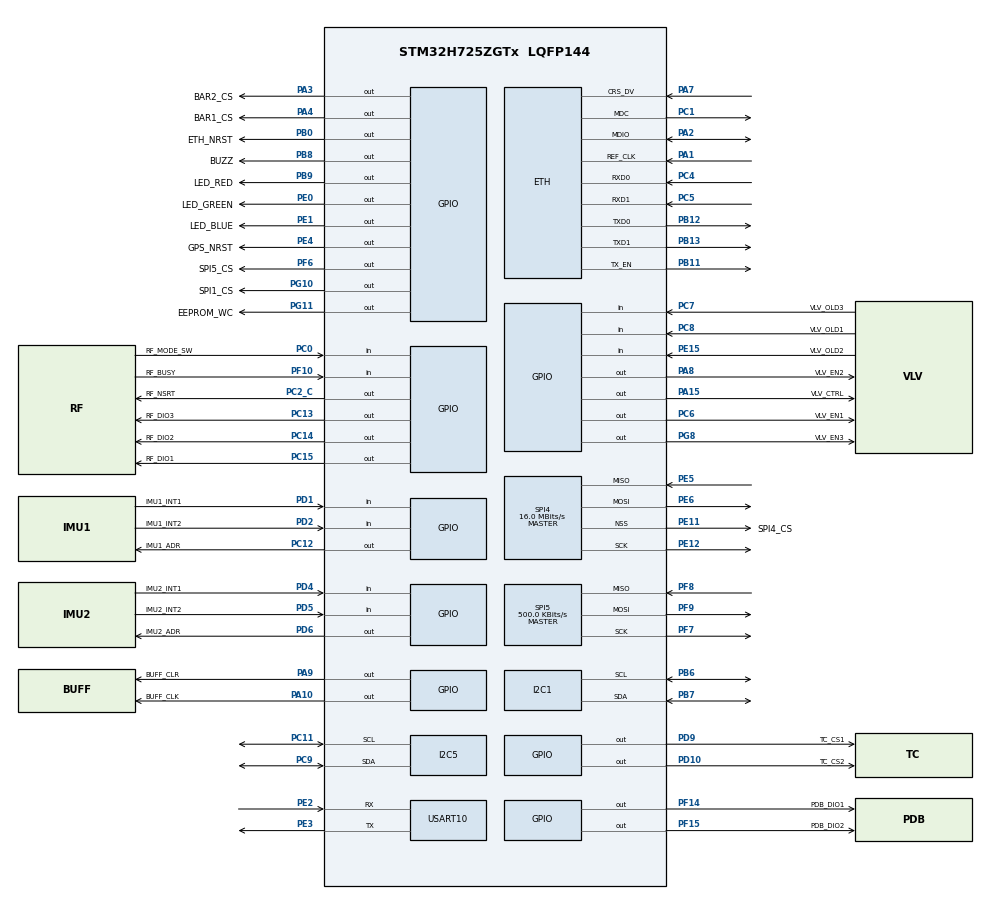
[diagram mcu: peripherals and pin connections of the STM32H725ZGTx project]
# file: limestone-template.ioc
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CORTEX_M7.AccessPermission-Cortex_Memory_Protection_Unit_Region0_Settings=MPU_REGION_NO_ACCESS
CORTEX_M7.AccessPermission-Cortex_Memory_Protection_Unit_Region1_Settings=MPU_REGION_FULL_ACCESS
CORTEX_M7.AccessPermission-Cortex_Memory_Protection_Unit_Region2_Settings=MPU_REGION_FULL_ACCESS
CORTEX_M7.AccessPermission_S-Cortex_Memory_Protection_Unit_Region1_Settings_S=MPU_REGION_FULL_ACCESS
CORTEX_M7.AccessPermission_S-Cortex_Memory_Protection_Unit_Region2_Settings_S=MPU_REGION_FULL_ACCESS
CORTEX_M7.AccessPermission_Spec=MPU_REGION_NO_ACCESS
CORTEX_M7.BaseAddress-Cortex_Memory_Protection_Unit_Region0_Settings=0x00000000
CORTEX_M7.BaseAddress-Cortex_Memory_Protection_Unit_Region1_Settings=0x30000200
CORTEX_M7.BaseAddress-Cortex_Memory_Protection_Unit_Region2_Settings=0x30000000
CORTEX_M7.BaseAddress_S-Cortex_Memory_Protection_Unit_Region1_Settings_S=0x30020000
CORTEX_M7.BaseAddress_S-Cortex_Memory_Protection_Unit_Region2_Settings_S=0x30040000
CORTEX_M7.CPU_DCache=Enabled
CORTEX_M7.CPU_ICache=Enabled
CORTEX_M7.DisableExec-Cortex_Memory_Protection_Unit_Region0_Settings=MPU_INSTRUCTION_ACCESS_DISABLE
CORTEX_M7.DisableExec-Cortex_Memory_Protection_Unit_Region1_Settings=MPU_INSTRUCTION_ACCESS_DISABLE
CORTEX_M7.DisableExec-Cortex_Memory_Protection_Unit_Region2_Settings=MPU_INSTRUCTION_ACCESS_DISABLE
CORTEX_M7.DisableExec_S-Cortex_Memory_Protection_Unit_Region1_Settings_S=MPU_INSTRUCTION_ACCESS_DISABLE
CORTEX_M7.DisableExec_S-Cortex_Memory_Protection_Unit_Region2_Settings_S=MPU_INSTRUCTION_ACCESS_DISABLE
CORTEX_M7.Enable-Cortex_Memory_Protection_Unit_Region0_Settings=MPU_REGION_ENABLE
CORTEX_M7.Enable-Cortex_Memory_Protection_Unit_Region1_Settings=MPU_REGION_ENABLE
CORTEX_M7.Enable-Cortex_Memory_Protection_Unit_Region2_Settings=MPU_REGION_ENABLE
CORTEX_M7.Enable_S-Cortex_Memory_Protection_Unit_Region1_Settings_S=MPU_REGION_ENABLE
CORTEX_M7.Enable_S-Cortex_Memory_Protection_Unit_Region2_Settings_S=MPU_REGION_ENABLE
CORTEX_M7.IsBufferable-Cortex_Memory_Protection_Unit_Region1_Settings=MPU_ACCESS_NOT_BUFFERABLE
CORTEX_M7.IsBufferable-Cortex_Memory_Protection_Unit_Region2_Settings=MPU_ACCESS_BUFFERABLE
CORTEX_M7.IsBufferable_S-Cortex_Memory_Protection_Unit_Region2_Settings_S=MPU_ACCESS_BUFFERABLE
CORTEX_M7.IsCacheable-Cortex_Memory_Protection_Unit_Region1_Settings=MPU_ACCESS_NOT_CACHEABLE
CORTEX_M7.IsShareable-Cortex_Memory_Protection_Unit_Region0_Settings=MPU_ACCESS_SHAREABLE
CORTEX_M7.IsShareable-Cortex_Memory_Protection_Unit_Region2_Settings=MPU_ACCESS_SHAREABLE
CORTEX_M7.IsShareable_S-Cortex_Memory_Protection_Unit_Region1_Settings_S=MPU_ACCESS_NOT_SHAREABLE
CORTEX_M7.IsShareable_S-Cortex_Memory_Protection_Unit_Region2_Settings_S=MPU_ACCESS_SHAREABLE
CORTEX_M7.MPU_Control=MPU_PRIVILEGED_DEFAULT
CORTEX_M7.Size-Cortex_Memory_Protection_Unit_Region0_Settings=MPU_REGION_SIZE_4GB
CORTEX_M7.Size-Cortex_Memory_Protection_Unit_Region1_Settings=MPU_REGION_SIZE_128KB
CORTEX_M7.Size-Cortex_Memory_Protection_Unit_Region2_Settings=MPU_REGION_SIZE_512B
CORTEX_M7.Size_S-Cortex_Memory_Protection_Unit_Region1_Settings_S=MPU_REGION_SIZE_128KB
CORTEX_M7.Size_S-Cortex_Memory_Protection_Unit_Region2_Settings_S=MPU_REGION_SIZE_512B
CORTEX_M7.SubRegionDisable-Cortex_Memory_Protection_Unit_Region0_Settings=0x87
CORTEX_M7.SubRegionDisable_S-Cortex_Memory_Protection_Unit_Region1_Settings_S=0x0
CORTEX_M7.TypeExtField-Cortex_Memory_Protection_Unit_Region1_Settings=MPU_TEX_LEVEL1
CORTEX_M7.TypeExtField_S-Cortex_Memory_Protection_Unit_Region1_Settings_S=MPU_TEX_LEVEL1
CORTEX_M7.default_mode_Activation=1
ETH.MediaInterface=HAL_ETH_RMII_MODE
ETH.RxBuffLen=1524
ETH.TxDescAddress=0x30000080
FREERTOS.Tasks01=defaultTask,24,512,StartDefaultTask,Default,NULL,Dynamic,NULL,NULL
FREERTOS.configUSE_NEWLIB_REENTRANT=1
I2C1.Timing=0x00707CBB
I2C5.Timing=0x00707CBB
Mcu.Family=STM32H7
Mcu.Name=STM32H725ZGTx
Mcu.Package=LQFP144
NVIC.ETH_IRQn=true\:5\:0\:true\:false\:true\:true\:true\:true\:true
NVIC.PriorityGroup=NVIC_PRIORITYGROUP_4
NVIC.TIM6_DAC_IRQn=true\:15\:0\:false\:false\:true\:false\:false\:true\:true
NVIC.TimeBase=TIM6_DAC_IRQn
NVIC.TimeBaseIP=TIM6
PA1.GPIO_Speed=GPIO_SPEED_FREQ_VERY_HIGH
PA1.Mode=RMII
PA1.Signal=ETH_REF_CLK
PA10.GPIO_Label=BUFF_CLK
PA10.GPIO_Speed=GPIO_SPEED_FREQ_VERY_HIGH
PA10.Signal=GPIO_Output
PA13(JTMS/SWDIO).Mode=Serial_Wire
PA13(JTMS/SWDIO).Signal=DEBUG_JTMS-SWDIO
PA14(JTCK/SWCLK).Mode=Serial_Wire
PA14(JTCK/SWCLK).Signal=DEBUG_JTCK-SWCLK
PA15(JTDI).GPIO_Label=VLV_CTRL
PA15(JTDI).GPIO_PuPd=GPIO_NOPULL
PA15(JTDI).GPIO_Speed=GPIO_SPEED_FREQ_VERY_HIGH
PA15(JTDI).Signal=GPIO_Output
PA2.GPIO_Speed=GPIO_SPEED_FREQ_VERY_HIGH
PA2.Mode=RMII
PA2.Signal=ETH_MDIO
PA3.GPIO_Label=BAR2_CS
PA3.Signal=GPIO_Output
PA4.GPIO_Label=BAR1_CS
PA4.Signal=GPIO_Output
PA6.Signal=SPI1_MISO
PA7.GPIO_Speed=GPIO_SPEED_FREQ_VERY_HIGH
PA7.Mode=RMII
PA7.Signal=ETH_CRS_DV
PA8.GPIO_Label=VLV_EN2
PA8.Signal=GPIO_Output
PA9.GPIO_Label=BUFF_CLR
PA9.GPIO_Speed=GPIO_SPEED_FREQ_VERY_HIGH
PA9.Signal=GPIO_Output
PB0.GPIO_Label=ETH_NRST
PB0.Signal=GPIO_Output
PB10.Signal=SPI2_SCK
PB11.GPIO_Speed=GPIO_SPEED_FREQ_VERY_HIGH
PB11.Mode=RMII
PB11.Signal=ETH_TX_EN
PB12.GPIO_Speed=GPIO_SPEED_FREQ_VERY_HIGH
PB12.Mode=RMII
PB12.Signal=ETH_TXD0
PB13.GPIO_Speed=GPIO_SPEED_FREQ_VERY_HIGH
PB13.Mode=RMII
PB13.Signal=ETH_TXD1
PB14.Signal=SPI2_MISO
PB15.Signal=SPI2_MOSI
PB2.Signal=SPI3_MOSI
PB3(JTDO/TRACESWO).Signal=SPI1_SCK
PB4(NJTRST).Signal=SPI3_MISO
PB5.Signal=SPI1_MOSI
PB6.Mode=I2C
PB6.Signal=I2C1_SCL
PB7.Mode=I2C
PB7.Signal=I2C1_SDA
PB8.GPIO_Label=BUZZ
PB8.Signal=GPIO_Output
PB9.GPIO_Label=LED_RED
PB9.Signal=GPIO_Output
PC0.GPIO_Label=RF_MODE_SW
PC0.Signal=GPIO_Input
PC1.GPIO_Speed=GPIO_SPEED_FREQ_VERY_HIGH
PC1.Mode=RMII
PC1.Signal=ETH_MDC
PC10.Signal=SPI3_SCK
PC11.Mode=I2C
PC11.Signal=I2C5_SCL
PC12.GPIO_Label=IMU1_ADR
PC12.Signal=GPIO_Output
PC13.GPIO_Label=RF_DIO3
PC13.Signal=GPIO_Output
PC14-OSC32_IN.GPIO_Label=RF_DIO2
PC14-OSC32_IN.Signal=GPIO_Output
PC15-OSC32_OUT.GPIO_Label=RF_DIO1
PC15-OSC32_OUT.Signal=GPIO_Output
PC2_C.GPIO_Label=RF_NSRT
PC2_C.Signal=GPIO_Output
PC4.GPIO_Speed=GPIO_SPEED_FREQ_VERY_HIGH
PC4.Mode=RMII
PC4.Signal=ETH_RXD0
PC5.GPIO_Speed=GPIO_SPEED_FREQ_VERY_HIGH
PC5.Mode=RMII
PC5.Signal=ETH_RXD1
PC6.GPIO_Label=VLV_EN1
PC6.Signal=GPIO_Output
PC7.GPIO_Label=VLV_OLD3
PC7.Signal=GPIO_Input
PC8.GPIO_Label=VLV_OLD1
PC8.Signal=GPIO_Input
PC9.Mode=I2C
PC9.Signal=I2C5_SDA
PD1.GPIO_Label=IMU1_INT1
PD1.Signal=GPIO_Input
PD10.GPIO_Label=TC_CS2
PD10.Signal=GPIO_Output
PD2.GPIO_Label=IMU1_INT2
PD2.Signal=GPIO_Input
PD4.GPIO_Label=IMU2_INT1
PD4.Signal=GPIO_Input
PD5.GPIO_Label=IMU2_INT2
PD5.Signal=GPIO_Input
PD6.GPIO_Label=IMU2_ADR
PD6.Signal=GPIO_Output
PD9.GPIO_Label=TC_CS1
PD9.Signal=GPIO_Output
PE0.GPIO_Label=LED_GREEN
PE0.Signal=GPIO_Output
PE1.GPIO_Label=LED_BLUE
PE1.Signal=GPIO_Output
PE11.GPIO_Label=SPI4_CS
PE11.Mode=NSS_Signal_Hard_Output
PE11.Signal=SPI4_NSS
PE12.Mode=Full_Duplex_Master
PE12.Signal=SPI4_SCK
PE15.GPIO_Label=VLV_OLD2
PE15.Signal=GPIO_Input
PE2.Mode=Asynchronous
PE2.Signal=USART10_RX
PE3.Mode=Asynchronous
PE3.Signal=USART10_TX
PE4.GPIO_Label=GPS_NRST
PE4.Signal=GPIO_Output
PE5.Mode=Full_Duplex_Master
PE5.Signal=SPI4_MISO
PE6.Mode=Full_Duplex_Master
PE6.Signal=SPI4_MOSI
PF10.GPIO_Label=RF_BUSY
PF10.Signal=GPIO_Input
PF14.GPIO_Label=PDB_DIO1
PF14.Signal=GPIO_Output
PF15.GPIO_Label=PDB_DIO2
PF15.Signal=GPIO_Output
PF6.GPIO_Label=SPI5_CS
PF6.Signal=GPIO_Output
PF7.Mode=Full_Duplex_Master
PF7.Signal=SPI5_SCK
PF8.Mode=Full_Duplex_Master
PF8.Signal=SPI5_MISO
PF9.Mode=Full_Duplex_Master
PF9.Signal=SPI5_MOSI
PG10.GPIO_Label=SPI1_CS
PG10.Signal=GPIO_Output
PG11.GPIO_Label=EEPROM_WC
PG11.Signal=GPIO_Output
PG12.Signal=SPI6_MISO
PG14.Signal=SPI6_MOSI
PG8.GPIO_Label=VLV_EN3
PG8.Signal=GPIO_Output
ProjectManager.HeapSize=0x200
ProjectManager.StackSize=0x400
ProjectManager.TargetToolchain=STM32CubeIDE
RCC.ADCFreq_Value=516000000
RCC.APB1Freq_Value=32000000
RCC.APB2Freq_Value=32000000
RCC.APB3Freq_Value=32000000
RCC.APB4Freq_Value=32000000
RCC.CortexFreq_Value=64000000
RCC.D1PPRE=RCC_APB3_DIV2
RCC.D2PPRE1=RCC_APB1_DIV2
RCC.D2PPRE2=RCC_APB2_DIV2
RCC.D3PPRE=RCC_APB4_DIV2
RCC.DIVM1=4
RCC.DIVM2=8
RCC.DIVM3=8
RCC.DIVN1=12
RCC.DIVP1=3
RCC.DIVQ1=3
RCC.HCLKFreq_Value=64000000
RCC.HSE_VALUE=48000000
RCC.PLL2FRACN=0
RCC.PLL3FRACN=0
RCC.PLLFRACN=0
RCC.SYSCLKFreq_VALUE=64000000
RCC.SYSCLKSource=RCC_SYSCLKSOURCE_PLLCLK
RCC.SupplySource=PWR_LDO_SUPPLY
RCC.USBFreq_Value=64000000
SPI4.CalculateBaudRate=16.0 MBits/s
SPI4.DataSize=SPI_DATASIZE_8BIT
SPI4.Direction=SPI_DIRECTION_2LINES
SPI4.Mode=SPI_MODE_MASTER
SPI4.VirtualNSS=VM_NSSHARD
SPI4.VirtualType=VM_MASTER
SPI5.BaudRatePrescaler=SPI_BAUDRATEPRESCALER_64
SPI5.CalculateBaudRate=500.0 KBits/s
SPI5.DataSize=SPI_DATASIZE_8BIT
SPI5.Direction=SPI_DIRECTION_2LINES
SPI5.Mode=SPI_MODE_MASTER
SPI5.VirtualType=VM_MASTER
USART10.VirtualMode-Asynchronous=VM_ASYNC
VP_FREERTOS_VS_CMSIS_V2.Mode=CMSIS_V2
VP_MEMORYMAP_VS_MEMORYMAP.Mode=CurAppReg
VP_RTC_VS_RTC_Activate.Mode=RTC_Enabled
VP_SYS_VS_tim6.Mode=TIM6
board=custom

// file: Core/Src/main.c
/* USER CODE BEGIN Header */
/**
  ******************************************************************************
  * @file           : main.c
  * @brief          : Main program body
  ******************************************************************************
  * @attention
  *
  * Copyright (c) 2024 STMicroelectronics.
  * All rights reserved.
  *
  * This software is licensed under terms that can be found in the LICENSE file
  * in the root directory of this software component.
  * If no LICENSE file comes with this software, it is provided AS-IS.
  *
  ******************************************************************************
  */
/* USER CODE END Header */
#include "main.h"
#include "string.h"
#include "cmsis_os.h"

/* USER CODE BEGIN Includes */
#include "MS5611.h"
/* USER CODE END Includes */

#if defined ( __ICCARM__ ) /*!< IAR Compiler */
#pragma location=0x30000000
ETH_DMADescTypeDef  DMARxDscrTab[ETH_RX_DESC_CNT]; /* Ethernet Rx DMA Descriptors */
#pragma location=0x30000080
ETH_DMADescTypeDef  DMATxDscrTab[ETH_TX_DESC_CNT]; /* Ethernet Tx DMA Descriptors */

#elif defined ( __CC_ARM )  /* MDK ARM Compiler */

__attribute__((at(0x30000000))) ETH_DMADescTypeDef  DMARxDscrTab[ETH_RX_DESC_CNT]; /* Ethernet Rx DMA Descriptors */
__attribute__((at(0x30000080))) ETH_DMADescTypeDef  DMATxDscrTab[ETH_TX_DESC_CNT]; /* Ethernet Tx DMA Descriptors */

#elif defined ( __GNUC__ ) /* GNU Compiler */

ETH_DMADescTypeDef DMARxDscrTab[ETH_RX_DESC_CNT] __attribute__((section(".RxDescripSection"))); /* Ethernet Rx DMA Descriptors */
ETH_DMADescTypeDef DMATxDscrTab[ETH_TX_DESC_CNT] __attribute__((section(".TxDescripSection")));   /* Ethernet Tx DMA Descriptors */
#endif

ETH_TxPacketConfig TxConfig;

ETH_HandleTypeDef heth;

I2C_HandleTypeDef hi2c1;
I2C_HandleTypeDef hi2c5;

RTC_HandleTypeDef hrtc;

SPI_HandleTypeDef hspi4;
SPI_HandleTypeDef hspi5;

UART_HandleTypeDef huart10;

/* Definitions for defaultTask */
osThreadId_t defaultTaskHandle;
const osThreadAttr_t defaultTask_attributes = {
  .name = "defaultTask",
  .stack_size = 512 * 4,
  .priority = (osPriority_t) osPriorityNormal,
};

void SystemClock_Config(void);
static void MPU_Config(void);
static void MX_GPIO_Init(void);
static void MX_I2C1_Init(void);
static void MX_I2C5_Init(void);
static void MX_SPI4_Init(void);
static void MX_SPI5_Init(void);
static void MX_USART10_UART_Init(void);
static void MX_RTC_Init(void);
static void MX_ETH_Init(void);
void StartDefaultTask(void *argument);

int main(void)
{

  /* USER CODE BEGIN 1 */
  //SCB->VTOR = FLASH_BASE; // fuck this stupid bug kys
  /* USER CODE END 1 */

  /* MPU Configuration--------------------------------------------------------*/
  MPU_Config();

  /* Enable the CPU Cache */

  /* Enable I-Cache---------------------------------------------------------*/
  SCB_EnableICache();

  /* Enable D-Cache---------------------------------------------------------*/
  SCB_EnableDCache();

  /* MCU Configuration--------------------------------------------------------*/

  /* Reset of all peripherals, Initializes the Flash interface and the Systick. */
  HAL_Init();

  /* Configure the system clock */
  SystemClock_Config();

  /* Initialize all configured peripherals */
  MX_GPIO_Init();
  MX_I2C1_Init();
  MX_I2C5_Init();
  MX_SPI4_Init();
  MX_SPI5_Init();
  MX_USART10_UART_Init();
  MX_RTC_Init();
  MX_ETH_Init();

  /* Init scheduler */
  osKernelInitialize();

  /* Create the thread(s) */
  /* creation of defaultTask */
  defaultTaskHandle = osThreadNew(StartDefaultTask, NULL, &defaultTask_attributes);

  /* Start scheduler */
  osKernelStart();

  /* We should never get here as control is now taken by the scheduler */

  /* Infinite loop */
  while (1)
  {

  }
}

void SystemClock_Config(void)
{
  RCC_OscInitTypeDef RCC_OscInitStruct = {0};
  RCC_ClkInitTypeDef RCC_ClkInitStruct = {0};

  /** Supply configuration update enable
  */
  HAL_PWREx_ConfigSupply(PWR_LDO_SUPPLY);

  /** Configure the main internal regulator output voltage
  */
  __HAL_PWR_VOLTAGESCALING_CONFIG(PWR_REGULATOR_VOLTAGE_SCALE3);

  while(!__HAL_PWR_GET_FLAG(PWR_FLAG_VOSRDY)) {}

  /** Initializes the RCC Oscillators according to the specified parameters
  * in the RCC_OscInitTypeDef structure.
  */
  RCC_OscInitStruct.OscillatorType = RCC_OSCILLATORTYPE_HSI|RCC_OSCILLATORTYPE_LSI;
  RCC_OscInitStruct.HSIState = RCC_HSI_DIV1;
  RCC_OscInitStruct.HSICalibrationValue = 64;
  RCC_OscInitStruct.LSIState = RCC_LSI_ON;
  RCC_OscInitStruct.PLL.PLLState = RCC_PLL_ON;
  RCC_OscInitStruct.PLL.PLLSource = RCC_PLLSOURCE_HSI;
  RCC_OscInitStruct.PLL.PLLM = 4;
  RCC_OscInitStruct.PLL.PLLN = 12;
  RCC_OscInitStruct.PLL.PLLP = 3;
  RCC_OscInitStruct.PLL.PLLQ = 3;
  RCC_OscInitStruct.PLL.PLLR = 2;
  RCC_OscInitStruct.PLL.PLLRGE = RCC_PLL1VCIRANGE_3;
  RCC_OscInitStruct.PLL.PLLVCOSEL = RCC_PLL1VCOWIDE;
  RCC_OscInitStruct.PLL.PLLFRACN = 0;
  if (HAL_RCC_OscConfig(&RCC_OscInitStruct) != HAL_OK)
  {
    Error_Handler();
  }

  /** Initializes the CPU, AHB and APB buses clocks
  */
  RCC_ClkInitStruct.ClockType = RCC_CLOCKTYPE_HCLK|RCC_CLOCKTYPE_SYSCLK
                              |RCC_CLOCKTYPE_PCLK1|RCC_CLOCKTYPE_PCLK2
                              |RCC_CLOCKTYPE_D3PCLK1|RCC_CLOCKTYPE_D1PCLK1;
  RCC_ClkInitStruct.SYSCLKSource = RCC_SYSCLKSOURCE_PLLCLK;
  RCC_ClkInitStruct.SYSCLKDivider = RCC_SYSCLK_DIV1;
  RCC_ClkInitStruct.AHBCLKDivider = RCC_HCLK_DIV1;
  RCC_ClkInitStruct.APB3CLKDivider = RCC_APB3_DIV2;
  RCC_ClkInitStruct.APB1CLKDivider = RCC_APB1_DIV2;
  RCC_ClkInitStruct.APB2CLKDivider = RCC_APB2_DIV2;
  RCC_ClkInitStruct.APB4CLKDivider = RCC_APB4_DIV2;

  if (HAL_RCC_ClockConfig(&RCC_ClkInitStruct, FLASH_LATENCY_1) != HAL_OK)
  {
    Error_Handler();
  }
}

static void MX_ETH_Init(void)
{

   static uint8_t MACAddr[6];

  heth.Instance = ETH;
  MACAddr[0] = 0x00;
  MACAddr[1] = 0x80;
  MACAddr[2] = 0xE1;
  MACAddr[3] = 0x00;
  MACAddr[4] = 0x00;
  MACAddr[5] = 0x00;
  heth.Init.MACAddr = &MACAddr[0];
  heth.Init.MediaInterface = HAL_ETH_RMII_MODE;
  heth.Init.TxDesc = DMATxDscrTab;
  heth.Init.RxDesc = DMARxDscrTab;
  heth.Init.RxBuffLen = 1524;

  if (HAL_ETH_Init(&heth) != HAL_OK)
  {
    Error_Handler();
  }

  memset(&TxConfig, 0 , sizeof(ETH_TxPacketConfig));
  TxConfig.Attributes = ETH_TX_PACKETS_FEATURES_CSUM | ETH_TX_PACKETS_FEATURES_CRCPAD;
  TxConfig.ChecksumCtrl = ETH_CHECKSUM_IPHDR_PAYLOAD_INSERT_PHDR_CALC;
  TxConfig.CRCPadCtrl = ETH_CRC_PAD_INSERT;

}

static void MX_I2C1_Init(void)
{

  hi2c1.Instance = I2C1;
  hi2c1.Init.Timing = 0x00707CBB;
  hi2c1.Init.OwnAddress1 = 0;
  hi2c1.Init.AddressingMode = I2C_ADDRESSINGMODE_7BIT;
  hi2c1.Init.DualAddressMode = I2C_DUALADDRESS_DISABLE;
  hi2c1.Init.OwnAddress2 = 0;
  hi2c1.Init.OwnAddress2Masks = I2C_OA2_NOMASK;
  hi2c1.Init.GeneralCallMode = I2C_GENERALCALL_DISABLE;
  hi2c1.Init.NoStretchMode = I2C_NOSTRETCH_DISABLE;
  if (HAL_I2C_Init(&hi2c1) != HAL_OK)
  {
    Error_Handler();
  }

  /** Configure Analogue filter
  */
  if (HAL_I2CEx_ConfigAnalogFilter(&hi2c1, I2C_ANALOGFILTER_ENABLE) != HAL_OK)
  {
    Error_Handler();
  }

  /** Configure Digital filter
  */
  if (HAL_I2CEx_ConfigDigitalFilter(&hi2c1, 0) != HAL_OK)
  {
    Error_Handler();
  }

}

static void MX_I2C5_Init(void)
{

  hi2c5.Instance = I2C5;
  hi2c5.Init.Timing = 0x00707CBB;
  hi2c5.Init.OwnAddress1 = 0;
  hi2c5.Init.AddressingMode = I2C_ADDRESSINGMODE_7BIT;
  hi2c5.Init.DualAddressMode = I2C_DUALADDRESS_DISABLE;
  hi2c5.Init.OwnAddress2 = 0;
  hi2c5.Init.OwnAddress2Masks = I2C_OA2_NOMASK;
  hi2c5.Init.GeneralCallMode = I2C_GENERALCALL_DISABLE;
  hi2c5.Init.NoStretchMode = I2C_NOSTRETCH_DISABLE;
  if (HAL_I2C_Init(&hi2c5) != HAL_OK)
  {
    Error_Handler();
  }

  /** Configure Analogue filter
  */
  if (HAL_I2CEx_ConfigAnalogFilter(&hi2c5, I2C_ANALOGFILTER_ENABLE) != HAL_OK)
  {
    Error_Handler();
  }

  /** Configure Digital filter
  */
  if (HAL_I2CEx_ConfigDigitalFilter(&hi2c5, 0) != HAL_OK)
  {
    Error_Handler();
  }

}

static void MX_RTC_Init(void)
{

  /** Initialize RTC Only
  */
  hrtc.Instance = RTC;
  hrtc.Init.HourFormat = RTC_HOURFORMAT_24;
  hrtc.Init.AsynchPrediv = 127;
  hrtc.Init.SynchPrediv = 255;
  hrtc.Init.OutPut = RTC_OUTPUT_DISABLE;
  hrtc.Init.OutPutPolarity = RTC_OUTPUT_POLARITY_HIGH;
  hrtc.Init.OutPutType = RTC_OUTPUT_TYPE_OPENDRAIN;
  hrtc.Init.OutPutRemap = RTC_OUTPUT_REMAP_NONE;
  if (HAL_RTC_Init(&hrtc) != HAL_OK)
  {
    Error_Handler();
  }

}

static void MX_SPI4_Init(void)
{

  /* SPI4 parameter configuration*/
  hspi4.Instance = SPI4;
  hspi4.Init.Mode = SPI_MODE_MASTER;
  hspi4.Init.Direction = SPI_DIRECTION_2LINES;
  hspi4.Init.DataSize = SPI_DATASIZE_8BIT;
  hspi4.Init.CLKPolarity = SPI_POLARITY_LOW;
  hspi4.Init.CLKPhase = SPI_PHASE_1EDGE;
  hspi4.Init.NSS = SPI_NSS_HARD_OUTPUT;
  hspi4.Init.BaudRatePrescaler = SPI_BAUDRATEPRESCALER_2;
  hspi4.Init.FirstBit = SPI_FIRSTBIT_MSB;
  hspi4.Init.TIMode = SPI_TIMODE_DISABLE;
  hspi4.Init.CRCCalculation = SPI_CRCCALCULATION_DISABLE;
  hspi4.Init.CRCPolynomial = 0x0;
  hspi4.Init.NSSPMode = SPI_NSS_PULSE_ENABLE;
  hspi4.Init.NSSPolarity = SPI_NSS_POLARITY_LOW;
  hspi4.Init.FifoThreshold = SPI_FIFO_THRESHOLD_01DATA;
  hspi4.Init.TxCRCInitializationPattern = SPI_CRC_INITIALIZATION_ALL_ZERO_PATTERN;
  hspi4.Init.RxCRCInitializationPattern = SPI_CRC_INITIALIZATION_ALL_ZERO_PATTERN;
  hspi4.Init.MasterSSIdleness = SPI_MASTER_SS_IDLENESS_00CYCLE;
  hspi4.Init.MasterInterDataIdleness = SPI_MASTER_INTERDATA_IDLENESS_00CYCLE;
  hspi4.Init.MasterReceiverAutoSusp = SPI_MASTER_RX_AUTOSUSP_DISABLE;
  hspi4.Init.MasterKeepIOState = SPI_MASTER_KEEP_IO_STATE_DISABLE;
  hspi4.Init.IOSwap = SPI_IO_SWAP_DISABLE;
  if (HAL_SPI_Init(&hspi4) != HAL_OK)
  {
    Error_Handler();
  }

}

static void MX_SPI5_Init(void)
{

  /* SPI5 parameter configuration*/
  hspi5.Instance = SPI5;
  hspi5.Init.Mode = SPI_MODE_MASTER;
  hspi5.Init.Direction = SPI_DIRECTION_2LINES;
  hspi5.Init.DataSize = SPI_DATASIZE_8BIT;
  hspi5.Init.CLKPolarity = SPI_POLARITY_LOW;
  hspi5.Init.CLKPhase = SPI_PHASE_1EDGE;
  hspi5.Init.NSS = SPI_NSS_SOFT;
  hspi5.Init.BaudRatePrescaler = SPI_BAUDRATEPRESCALER_64;
  hspi5.Init.FirstBit = SPI_FIRSTBIT_MSB;
  hspi5.Init.TIMode = SPI_TIMODE_DISABLE;
  hspi5.Init.CRCCalculation = SPI_CRCCALCULATION_DISABLE;
  hspi5.Init.CRCPolynomial = 0x0;
  hspi5.Init.NSSPMode = SPI_NSS_PULSE_ENABLE;
  hspi5.Init.NSSPolarity = SPI_NSS_POLARITY_LOW;
  hspi5.Init.FifoThreshold = SPI_FIFO_THRESHOLD_01DATA;
  hspi5.Init.TxCRCInitializationPattern = SPI_CRC_INITIALIZATION_ALL_ZERO_PATTERN;
  hspi5.Init.RxCRCInitializationPattern = SPI_CRC_INITIALIZATION_ALL_ZERO_PATTERN;
  hspi5.Init.MasterSSIdleness = SPI_MASTER_SS_IDLENESS_00CYCLE;
  hspi5.Init.MasterInterDataIdleness = SPI_MASTER_INTERDATA_IDLENESS_00CYCLE;
  hspi5.Init.MasterReceiverAutoSusp = SPI_MASTER_RX_AUTOSUSP_DISABLE;
  hspi5.Init.MasterKeepIOState = SPI_MASTER_KEEP_IO_STATE_DISABLE;
  hspi5.Init.IOSwap = SPI_IO_SWAP_DISABLE;
  if (HAL_SPI_Init(&hspi5) != HAL_OK)
  {
    Error_Handler();
  }

}

static void MX_USART10_UART_Init(void)
{

  huart10.Instance = USART10;
  huart10.Init.BaudRate = 115200;
  huart10.Init.WordLength = UART_WORDLENGTH_8B;
  huart10.Init.StopBits = UART_STOPBITS_1;
  huart10.Init.Parity = UART_PARITY_NONE;
  huart10.Init.Mode = UART_MODE_TX_RX;
  huart10.Init.HwFlowCtl = UART_HWCONTROL_NONE;
  huart10.Init.OverSampling = UART_OVERSAMPLING_16;
  huart10.Init.OneBitSampling = UART_ONE_BIT_SAMPLE_DISABLE;
  huart10.Init.ClockPrescaler = UART_PRESCALER_DIV1;
  huart10.AdvancedInit.AdvFeatureInit = UART_ADVFEATURE_NO_INIT;
  if (HAL_UART_Init(&huart10) != HAL_OK)
  {
    Error_Handler();
  }
  if (HAL_UARTEx_SetTxFifoThreshold(&huart10, UART_TXFIFO_THRESHOLD_1_8) != HAL_OK)
  {
    Error_Handler();
  }
  if (HAL_UARTEx_SetRxFifoThreshold(&huart10, UART_RXFIFO_THRESHOLD_1_8) != HAL_OK)
  {
    Error_Handler();
  }
  if (HAL_UARTEx_DisableFifoMode(&huart10) != HAL_OK)
  {
    Error_Handler();
  }

}

static void MX_GPIO_Init(void)
{
  GPIO_InitTypeDef GPIO_InitStruct = {0};

  /* GPIO Ports Clock Enable */
  __HAL_RCC_GPIOE_CLK_ENABLE();
  __HAL_RCC_GPIOC_CLK_ENABLE();
  __HAL_RCC_GPIOF_CLK_ENABLE();
  __HAL_RCC_GPIOA_CLK_ENABLE();
  __HAL_RCC_GPIOB_CLK_ENABLE();
  __HAL_RCC_GPIOD_CLK_ENABLE();
  __HAL_RCC_GPIOG_CLK_ENABLE();

  /*Configure GPIO pin Output Level */
  HAL_GPIO_WritePin(GPIOE, GPS_NRST_Pin|LED_GREEN_Pin|LED_BLUE_Pin, GPIO_PIN_RESET);

  /*Configure GPIO pin Output Level */
  HAL_GPIO_WritePin(GPIOC, RF_DIO3_Pin|RF_DIO2_Pin|RF_DIO1_Pin|RF_NSRT_Pin
                          |VLV_EN1_Pin|IMU1_ADR_Pin, GPIO_PIN_RESET);

  /*Configure GPIO pin Output Level */
  HAL_GPIO_WritePin(GPIOF, SPI5_CS_Pin|PDB_DIO1_Pin|PDB_DIO2_Pin, GPIO_PIN_RESET);

  /*Configure GPIO pin Output Level */
  HAL_GPIO_WritePin(GPIOA, BAR2_CS_Pin|BAR1_CS_Pin|VLV_EN2_Pin|BUFF_CLR_Pin
                          |BUFF_CLK_Pin|VLV_CTRL_Pin, GPIO_PIN_RESET);

  /*Configure GPIO pin Output Level */
  HAL_GPIO_WritePin(GPIOB, ETH_NRST_Pin|BUZZ_Pin|LED_RED_Pin, GPIO_PIN_RESET);

  /*Configure GPIO pin Output Level */
  HAL_GPIO_WritePin(GPIOD, TC_CS1_Pin|TC_CS2_Pin|IMU2_ADR_Pin, GPIO_PIN_RESET);

  /*Configure GPIO pin Output Level */
  HAL_GPIO_WritePin(GPIOG, VLV_EN3_Pin|SPI1_CS_Pin|EEPROM_WC_Pin, GPIO_PIN_RESET);

  /*Configure GPIO pins : GPS_NRST_Pin LED_GREEN_Pin LED_BLUE_Pin */
  GPIO_InitStruct.Pin = GPS_NRST_Pin|LED_GREEN_Pin|LED_BLUE_Pin;
  GPIO_InitStruct.Mode = GPIO_MODE_OUTPUT_PP;
  GPIO_InitStruct.Pull = GPIO_NOPULL;
  GPIO_InitStruct.Speed = GPIO_SPEED_FREQ_LOW;
  HAL_GPIO_Init(GPIOE, &GPIO_InitStruct);

  /*Configure GPIO pins : RF_DIO3_Pin RF_DIO2_Pin RF_DIO1_Pin RF_NSRT_Pin
                           VLV_EN1_Pin IMU1_ADR_Pin */
  GPIO_InitStruct.Pin = RF_DIO3_Pin|RF_DIO2_Pin|RF_DIO1_Pin|RF_NSRT_Pin
                          |VLV_EN1_Pin|IMU1_ADR_Pin;
  GPIO_InitStruct.Mode = GPIO_MODE_OUTPUT_PP;
  GPIO_InitStruct.Pull = GPIO_NOPULL;
  GPIO_InitStruct.Speed = GPIO_SPEED_FREQ_LOW;
  HAL_GPIO_Init(GPIOC, &GPIO_InitStruct);

  /*Configure GPIO pins : SPI5_CS_Pin PDB_DIO1_Pin PDB_DIO2_Pin */
  GPIO_InitStruct.Pin = SPI5_CS_Pin|PDB_DIO1_Pin|PDB_DIO2_Pin;
  GPIO_InitStruct.Mode = GPIO_MODE_OUTPUT_PP;
  GPIO_InitStruct.Pull = GPIO_NOPULL;
  GPIO_InitStruct.Speed = GPIO_SPEED_FREQ_LOW;
  HAL_GPIO_Init(GPIOF, &GPIO_InitStruct);

  /*Configure GPIO pin : RF_BUSY_Pin */
  GPIO_InitStruct.Pin = RF_BUSY_Pin;
  GPIO_InitStruct.Mode = GPIO_MODE_INPUT;
  GPIO_InitStruct.Pull = GPIO_NOPULL;
  HAL_GPIO_Init(RF_BUSY_GPIO_Port, &GPIO_InitStruct);

  /*Configure GPIO pins : RF_MODE_SW_Pin VLV_OLD3_Pin VLV_OLD1_Pin */
  GPIO_InitStruct.Pin = RF_MODE_SW_Pin|VLV_OLD3_Pin|VLV_OLD1_Pin;
  GPIO_InitStruct.Mode = GPIO_MODE_INPUT;
  GPIO_InitStruct.Pull = GPIO_NOPULL;
  HAL_GPIO_Init(GPIOC, &GPIO_InitStruct);

  /*Configure GPIO pins : BAR2_CS_Pin BAR1_CS_Pin VLV_EN2_Pin */
  GPIO_InitStruct.Pin = BAR2_CS_Pin|BAR1_CS_Pin|VLV_EN2_Pin;
  GPIO_InitStruct.Mode = GPIO_MODE_OUTPUT_PP;
  GPIO_InitStruct.Pull = GPIO_NOPULL;
  GPIO_InitStruct.Speed = GPIO_SPEED_FREQ_LOW;
  HAL_GPIO_Init(GPIOA, &GPIO_InitStruct);

  /*Configure GPIO pin : PA6 */
  GPIO_InitStruct.Pin = GPIO_PIN_6;
  GPIO_InitStruct.Mode = GPIO_MODE_AF_PP;
  GPIO_InitStruct.Pull = GPIO_NOPULL;
  GPIO_InitStruct.Speed = GPIO_SPEED_FREQ_LOW;
  GPIO_InitStruct.Alternate = GPIO_AF5_SPI1;
  HAL_GPIO_Init(GPIOA, &GPIO_InitStruct);

  /*Configure GPIO pins : ETH_NRST_Pin BUZZ_Pin LED_RED_Pin */
  GPIO_InitStruct.Pin = ETH_NRST_Pin|BUZZ_Pin|LED_RED_Pin;
  GPIO_InitStruct.Mode = GPIO_MODE_OUTPUT_PP;
  GPIO_InitStruct.Pull = GPIO_NOPULL;
  GPIO_InitStruct.Speed = GPIO_SPEED_FREQ_LOW;
  HAL_GPIO_Init(GPIOB, &GPIO_InitStruct);

  /*Configure GPIO pin : PB2 */
  GPIO_InitStruct.Pin = GPIO_PIN_2;
  GPIO_InitStruct.Mode = GPIO_MODE_AF_PP;
  GPIO_InitStruct.Pull = GPIO_NOPULL;
  GPIO_InitStruct.Speed = GPIO_SPEED_FREQ_LOW;
  GPIO_InitStruct.Alternate = GPIO_AF7_SPI3;
  HAL_GPIO_Init(GPIOB, &GPIO_InitStruct);

  /*Configure GPIO pin : VLV_OLD2_Pin */
  GPIO_InitStruct.Pin = VLV_OLD2_Pin;
  GPIO_InitStruct.Mode = GPIO_MODE_INPUT;
  GPIO_InitStruct.Pull = GPIO_NOPULL;
  HAL_GPIO_Init(VLV_OLD2_GPIO_Port, &GPIO_InitStruct);

  /*Configure GPIO pins : PB10 PB14 PB15 */
  GPIO_InitStruct.Pin = GPIO_PIN_10|GPIO_PIN_14|GPIO_PIN_15;
  GPIO_InitStruct.Mode = GPIO_MODE_AF_PP;
  GPIO_InitStruct.Pull = GPIO_NOPULL;
  GPIO_InitStruct.Speed = GPIO_SPEED_FREQ_LOW;
  GPIO_InitStruct.Alternate = GPIO_AF5_SPI2;
  HAL_GPIO_Init(GPIOB, &GPIO_InitStruct);

  /*Configure GPIO pins : TC_CS1_Pin TC_CS2_Pin IMU2_ADR_Pin */
  GPIO_InitStruct.Pin = TC_CS1_Pin|TC_CS2_Pin|IMU2_ADR_Pin;
  GPIO_InitStruct.Mode = GPIO_MODE_OUTPUT_PP;
  GPIO_InitStruct.Pull = GPIO_NOPULL;
  GPIO_InitStruct.Speed = GPIO_SPEED_FREQ_LOW;
  HAL_GPIO_Init(GPIOD, &GPIO_InitStruct);

  /*Configure GPIO pins : VLV_EN3_Pin SPI1_CS_Pin EEPROM_WC_Pin */
  GPIO_InitStruct.Pin = VLV_EN3_Pin|SPI1_CS_Pin|EEPROM_WC_Pin;
  GPIO_InitStruct.Mode = GPIO_MODE_OUTPUT_PP;
  GPIO_InitStruct.Pull = GPIO_NOPULL;
  GPIO_InitStruct.Speed = GPIO_SPEED_FREQ_LOW;
  HAL_GPIO_Init(GPIOG, &GPIO_InitStruct);

  /*Configure GPIO pins : BUFF_CLR_Pin BUFF_CLK_Pin VLV_CTRL_Pin */
  GPIO_InitStruct.Pin = BUFF_CLR_Pin|BUFF_CLK_Pin|VLV_CTRL_Pin;
  GPIO_InitStruct.Mode = GPIO_MODE_OUTPUT_PP;
  GPIO_InitStruct.Pull = GPIO_NOPULL;
  GPIO_InitStruct.Speed = GPIO_SPEED_FREQ_VERY_HIGH;
  HAL_GPIO_Init(GPIOA, &GPIO_InitStruct);

  /*Configure GPIO pin : PC10 */
  GPIO_InitStruct.Pin = GPIO_PIN_10;
  GPIO_InitStruct.Mode = GPIO_MODE_AF_PP;
  GPIO_InitStruct.Pull = GPIO_NOPULL;
  GPIO_InitStruct.Speed = GPIO_SPEED_FREQ_LOW;
  GPIO_InitStruct.Alternate = GPIO_AF6_SPI3;
  HAL_GPIO_Init(GPIOC, &GPIO_InitStruct);

  /*Configure GPIO pins : IMU1_INT1_Pin IMU1_INT2_Pin IMU2_INT1_Pin IMU2_INT2_Pin */
  GPIO_InitStruct.Pin = IMU1_INT1_Pin|IMU1_INT2_Pin|IMU2_INT1_Pin|IMU2_INT2_Pin;
  GPIO_InitStruct.Mode = GPIO_MODE_INPUT;
  GPIO_InitStruct.Pull = GPIO_NOPULL;
  HAL_GPIO_Init(GPIOD, &GPIO_InitStruct);

  /*Configure GPIO pins : PG12 PG14 */
  GPIO_InitStruct.Pin = GPIO_PIN_12|GPIO_PIN_14;
  GPIO_InitStruct.Mode = GPIO_MODE_AF_PP;
  GPIO_InitStruct.Pull = GPIO_NOPULL;
  GPIO_InitStruct.Speed = GPIO_SPEED_FREQ_LOW;
  GPIO_InitStruct.Alternate = GPIO_AF5_SPI6;
  HAL_GPIO_Init(GPIOG, &GPIO_InitStruct);

  /*Configure GPIO pins : PB3 PB5 */
  GPIO_InitStruct.Pin = GPIO_PIN_3|GPIO_PIN_5;
  GPIO_InitStruct.Mode = GPIO_MODE_AF_PP;
  GPIO_InitStruct.Pull = GPIO_NOPULL;
  GPIO_InitStruct.Speed = GPIO_SPEED_FREQ_LOW;
  GPIO_InitStruct.Alternate = GPIO_AF5_SPI1;
  HAL_GPIO_Init(GPIOB, &GPIO_InitStruct);

  /*Configure GPIO pin : PB4 */
  GPIO_InitStruct.Pin = GPIO_PIN_4;
  GPIO_InitStruct.Mode = GPIO_MODE_AF_PP;
  GPIO_InitStruct.Pull = GPIO_NOPULL;
  GPIO_InitStruct.Speed = GPIO_SPEED_FREQ_LOW;
  GPIO_InitStruct.Alternate = GPIO_AF6_SPI3;
  HAL_GPIO_Init(GPIOB, &GPIO_InitStruct);

  /*AnalogSwitch Config */
  HAL_SYSCFG_AnalogSwitchConfig(SYSCFG_SWITCH_PC2, SYSCFG_SWITCH_PC2_CLOSE);

}

void StartDefaultTask(void *argument)
{
  /* USER CODE BEGIN 5 */
    MS5611 baro = {0};
	baro.hspi = &hspi6;
	baro.CS_GPIO_Pin = BAR2_CS_Pin;
	baro.CS_GPIO_Port = BAR2_CS_GPIO_Port;
	baro.SPI_TIMEOUT = 1000;
	baro.pres_offset = 0;
	baro.alt_offset = 0;

	MS5611_PROM_t prom = {0};
	float pres = 0;

	MS5611_Reset(&baro);
	MS5611_readPROM(&baro, &prom);

	for (;;) {
		MS5611_getPres(&baro, &pres, OSR_256);
	}
  /* USER CODE END 5 */
}

 /* MPU Configuration */

void MPU_Config(void)
{
  MPU_Region_InitTypeDef MPU_InitStruct = {0};

  /* Disables the MPU */
  HAL_MPU_Disable();

  /** Initializes and configures the Region and the memory to be protected
  */
  MPU_InitStruct.Enable = MPU_REGION_ENABLE;
  MPU_InitStruct.Number = MPU_REGION_NUMBER0;
  MPU_InitStruct.BaseAddress = 0x0;
  MPU_InitStruct.Size = MPU_REGION_SIZE_4GB;
  MPU_InitStruct.SubRegionDisable = 0x87;
  MPU_InitStruct.TypeExtField = MPU_TEX_LEVEL0;
  MPU_InitStruct.AccessPermission = MPU_REGION_NO_ACCESS;
  MPU_InitStruct.DisableExec = MPU_INSTRUCTION_ACCESS_DISABLE;
  MPU_InitStruct.IsShareable = MPU_ACCESS_SHAREABLE;
  MPU_InitStruct.IsCacheable = MPU_ACCESS_NOT_CACHEABLE;
  MPU_InitStruct.IsBufferable = MPU_ACCESS_NOT_BUFFERABLE;

  HAL_MPU_ConfigRegion(&MPU_InitStruct);

  /** Initializes and configures the Region and the memory to be protected
  */
  MPU_InitStruct.Number = MPU_REGION_NUMBER1;
  MPU_InitStruct.BaseAddress = 0x30020000;
  MPU_InitStruct.Size = MPU_REGION_SIZE_128KB;
  MPU_InitStruct.SubRegionDisable = 0x0;
  MPU_InitStruct.TypeExtField = MPU_TEX_LEVEL1;
  MPU_InitStruct.AccessPermission = MPU_REGION_FULL_ACCESS;
  MPU_InitStruct.IsShareable = MPU_ACCESS_NOT_SHAREABLE;

  HAL_MPU_ConfigRegion(&MPU_InitStruct);

  /** Initializes and configures the Region and the memory to be protected
  */
  MPU_InitStruct.Number = MPU_REGION_NUMBER2;
  MPU_InitStruct.BaseAddress = 0x30040000;
  MPU_InitStruct.Size = MPU_REGION_SIZE_512B;
  MPU_InitStruct.TypeExtField = MPU_TEX_LEVEL0;
  MPU_InitStruct.IsShareable = MPU_ACCESS_SHAREABLE;
  MPU_InitStruct.IsBufferable = MPU_ACCESS_BUFFERABLE;

  HAL_MPU_ConfigRegion(&MPU_InitStruct);
  /* Enables the MPU */
  HAL_MPU_Enable(MPU_PRIVILEGED_DEFAULT);

}

void HAL_TIM_PeriodElapsedCallback(TIM_HandleTypeDef *htim)
{
  if (htim->Instance == TIM6)
  {
    HAL_IncTick();
  }
}

void Error_Handler(void)
{
  /* USER CODE BEGIN Error_Handler_Debug */
  /* User can add his own implementation to report the HAL error return state */
  //__disable_irq();
  while (1)
  {
  }
  /* USER CODE END Error_Handler_Debug */
}

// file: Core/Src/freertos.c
/* USER CODE BEGIN Header */
/**
  ******************************************************************************
  * File Name          : freertos.c
  * Description        : Code for freertos applications
  ******************************************************************************
  * @attention
  *
  * Copyright (c) 2024 STMicroelectronics.
  * All rights reserved.
  *
  * This software is licensed under terms that can be found in the LICENSE file
  * in the root directory of this software component.
  * If no LICENSE file comes with this software, it is provided AS-IS.
  *
  ******************************************************************************
  */
/* USER CODE END Header */

#include "FreeRTOS.h"
#include "task.h"
#include "main.h"

/* Hook prototypes */
void vApplicationStackOverflowHook(xTaskHandle xTask, signed char *pcTaskName);

/* USER CODE BEGIN 4 */
void vApplicationStackOverflowHook(xTaskHandle xTask, signed char *pcTaskName)
{
   /* Run time stack overflow checking is performed if
   configCHECK_FOR_STACK_OVERFLOW is defined to 1 or 2. This hook function is
   called if a stack overflow is detected. */
}
/* USER CODE END 4 */
